VERSION ""

NS_ :

BS_:

BU_: Telemetry

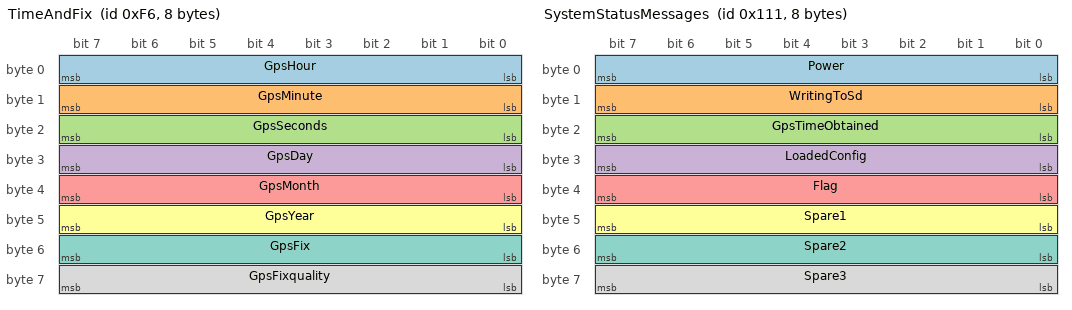
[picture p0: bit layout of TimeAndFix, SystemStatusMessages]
BO_ 246 TimeAndFix: 8 Telemetry
 SG_ GpsHour : 0|8@1+ (1,0) [0|60] "" Vector__XXX
 SG_ GpsMinute : 8|8@1+ (1,0) [0|60] "" Vector__XXX
 SG_ GpsSeconds : 16|8@1+ (1,0) [0|60] "" Vector__XXX
 SG_ GpsDay : 24|8@1+ (1,0) [1|31] "" Vector__XXX
 SG_ GpsMonth : 32|8@1+ (1,0) [1|12] "" Vector__XXX
 SG_ GpsYear : 40|8@1+ (1,0) [0|99] "" Vector__XXX
 SG_ GpsFix : 48|8@1+ (1,0) [0|0] "" Vector__XXX
 SG_ GpsFixquality : 56|8@1+ (1,0) [0|0] "" Vector__XXX

BO_ 247 SpeedAndAngle: 8 Telemetry
 SG_ GpsSpeed : 0|32@1- (1,0) [0|0] "" Vector__XXX
 SG_ GpsAngle : 32|32@1- (1,0) [0|0] "" Vector__XXX

BO_ 248 Latitude: 5 Telemetry
 SG_ GpsLatitude : 0|32@1- (1,0) [0|0] "" Vector__XXX
 SG_ GpsLat : 32|8@1+ (1,0) [0|0] "ascii" Vector__XXX

BO_ 249 Longitude: 5 Telemetry
 SG_ GpsLongitude : 0|32@1- (1,0) [0|0] "" Vector__XXX
 SG_ GpsLon : 32|8@1+ (1,0) [0|0] "ascii" Vector__XXX

BO_ 250 AltitudeAndSatellites: 5 Telemetry
 SG_ GpsAltitude : 0|32@1- (1,0) [0|0] "" Vector__XXX
 SG_ GpsSatellites : 32|8@1+ (1,0) [0|0] "" Vector__XXX

BO_ 273 SystemStatusMessages: 8 Telemetry
 SG_ Power : 0|8@1+ (1,0) [0|0] "" Vector__XXX
 SG_ WritingToSd : 8|8@1+ (1,0) [0|0] "" Vector__XXX
 SG_ GpsTimeObtained : 16|8@1+ (1,0) [0|0] "" Vector__XXX
 SG_ LoadedConfig : 24|8@1+ (1,0) [0|0] "" Vector__XXX
 SG_ Flag : 32|8@1+ (1,0) [0|0] "" Vector__XXX
 SG_ Spare1 : 40|8@1+ (1,0) [0|0] "" Vector__XXX
 SG_ Spare2 : 48|8@1+ (1,0) [0|0] "" Vector__XXX
 SG_ Spare3 : 56|8@1+ (1,0) [0|0] "" Vector__XXX

SIG_VALTYPE_ 247 GpsSpeed : 1;
SIG_VALTYPE_ 247 GpsAngle : 1;
SIG_VALTYPE_ 248 GpsLatitude : 1;
SIG_VALTYPE_ 249 GpsLongitude : 1;
SIG_VALTYPE_ 250 GpsAltitude : 1;

CM_ SG_ 248 GpsLat "NMEA latitude hemisphere character, N or S. Not a coordinate - GpsLatitude carries the position. The ascii unit marks it for char decoding in can_dbc_decoder.";
CM_ SG_ 249 GpsLon "NMEA longitude hemisphere character, E or W. Not a coordinate - GpsLongitude carries the position. The ascii unit marks it for char decoding in can_dbc_decoder.";
